# CY8C4145LQI_PS433 register map
File version: 0.1
PSoC 4100PS
Registers are 32-bit, read-write, no defined reset value unless marked. A register's access mark holds for its fields unless they carry their own. Offsets are from the block's base; lines under a group give offsets from that group; [hi:lo] are bit positions; {n}, {i} and the like mark numbered series; 'fields as' and 'values as' point back to an identical list; <NAME> marks a mode.

## Memory map
0x00000000 Opamp_1 — OpAmp
0x00000000 TCPWM_1
0x00000000 DMAC — DMAC Registers
0x00000000 PGA_1 — PGA
0x00000000 Timer_1
0x00000000 UART_1 — Serial Communication Block
0x00000000 ADC_1
0x00000000 I2C_1 — Serial Communication Block

## Opamp_1 — OpAmp
Base 0x00000000
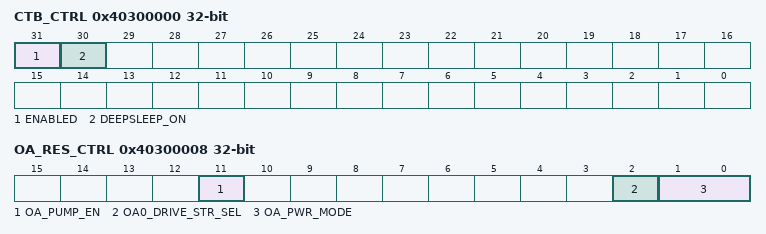
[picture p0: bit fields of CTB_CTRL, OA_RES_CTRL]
0x40300000 CTB_CTRL — Global CTB IP and power control
  [31] ENABLED — Selects component behavior in DeepSleep power mode
    0=DISABLE (CTB IP disabled (put analog in power down, open all switches)); 1=ENABLE (CTB IP enabledCTB IP enabled)
  [30] DEEPSLEEP_ON — Selects component behavior in DeepSleep power mode
    0=DISABLE (CTB IP disabled off during DeepSleep power mode); 1=ENABLE (CTB IP remains enabled during DeepSleep power mode (if ENABLED=1))
0x40300008 OA_RES_CTRL — Opamp and resistor control
  [11] OA_PUMP_EN — Selects pump
    0=DISABLE (Pump disabled); 1=ENABLE (Pump enabled)
  [2] OA0_DRIVE_STR_SEL — Opamp output strenght select
    0=Cy1x (Internal only); 1=Cy10x (Output to pin)
  [1:0] OA_PWR_MODE — Selects power for opamp
    0=OFF; 1=LOW (Low power); 2=MED (Medium power); 3=HIGH (High power)
0x40300F14 OA_COMP_TRIM — Opamp Compenation Capacitor Trim
  [1:0] OA_COMP_TRIM
    1=HIGH_SPEED; 2=BALANCED; 3=HIGH_STABILITY

## TCPWM_1
Base 0x00000000
0x40010148 COUNTER — Current counter value
0x4001014C CC — Compare / capture value
0x40010150 CC_BUF — Compare / capture buffer value
0x40010154 PERIOD — Period value
0x40010158 PERIOD_BUF — Period buffer value

## PGA_1 — PGA
Base 0x00000000
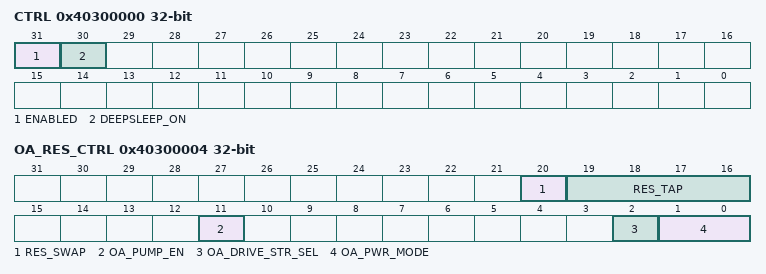
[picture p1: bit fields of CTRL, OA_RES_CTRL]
0x40300000 CTRL — Global CTB IP and power control
  [31] ENABLED — Selects component behavior in DeepSleep power mode
    0=DISABLE (CTB IP disabled (put analog in power down, open all switches)); 1=ENABLE (CTB IP enabledCTB IP enabled)
  [30] DEEPSLEEP_ON — Selects component behavior in DeepSleep power mode
    0=DISABLE (CTB IP disabled off during DeepSleep power mode); 1=ENABLE (CTB IP remains enabled during DeepSleep power mode (if ENABLED=1))
0x40300004 OA_RES_CTRL — Opamp and resistor control
  [20] RES_SWAP — Swaps Top and Bottom resistor value
    0=NORMAL (Normal mode); 1=SWAPPED (Top and Bottom are swapped)
  [19:16] RES_TAP — Selects PGA gain (resistor tap point)
    0=GAIN_1_0 (disconnect resistor); 1=GAIN_1_4; 2=GAIN_2_0; 3=GAIN_2_8; 4=GAIN_4_0; 5=GAIN_5_8; 6=GAIN_8_0; 7=GAIN_10_7; 8=GAIN_16_0; 9=GAIN_21_3; 10=GAIN_32_0 (max. gain)
  [11] OA_PUMP_EN — Selects pump
    0=DISABLE (Pump disabled); 1=ENABLE (Pump enabled)
  [2] OA_DRIVE_STR_SEL — Opamp output strenght select
    0=Cy1x (Internal only); 1=Cy10x (Output to pin)
  [1:0] OA_PWR_MODE — Selects power for opamp
    0=OFF; 1=LOW (Low power); 2=MED (Medium power); 3=HIGH (High power)
0x40300080 OA_SW — Opamp switch control
  [28] RES0_R6 ro — Resistor bottom to VSSA
    0=DISABLE; 1=ENABLE
0x40300F08 OA_COMP_TRIM — Opamp Compenation Capacitor Trim
  [1:0] OA_COMP_TRIM
    1=HIGH_SPEED; 2=BALANCED; 3=HIGH_STABILITY

## Timer_1
Base 0x00000000
0x40010108 COUNTER — Current counter value
0x4001010C CC — Compare / capture value
0x40010110 CC_BUF — Compare / capture buffer value
0x40010114 PERIOD — Period value
0x40010118 PERIOD_BUF — Period buffer value
